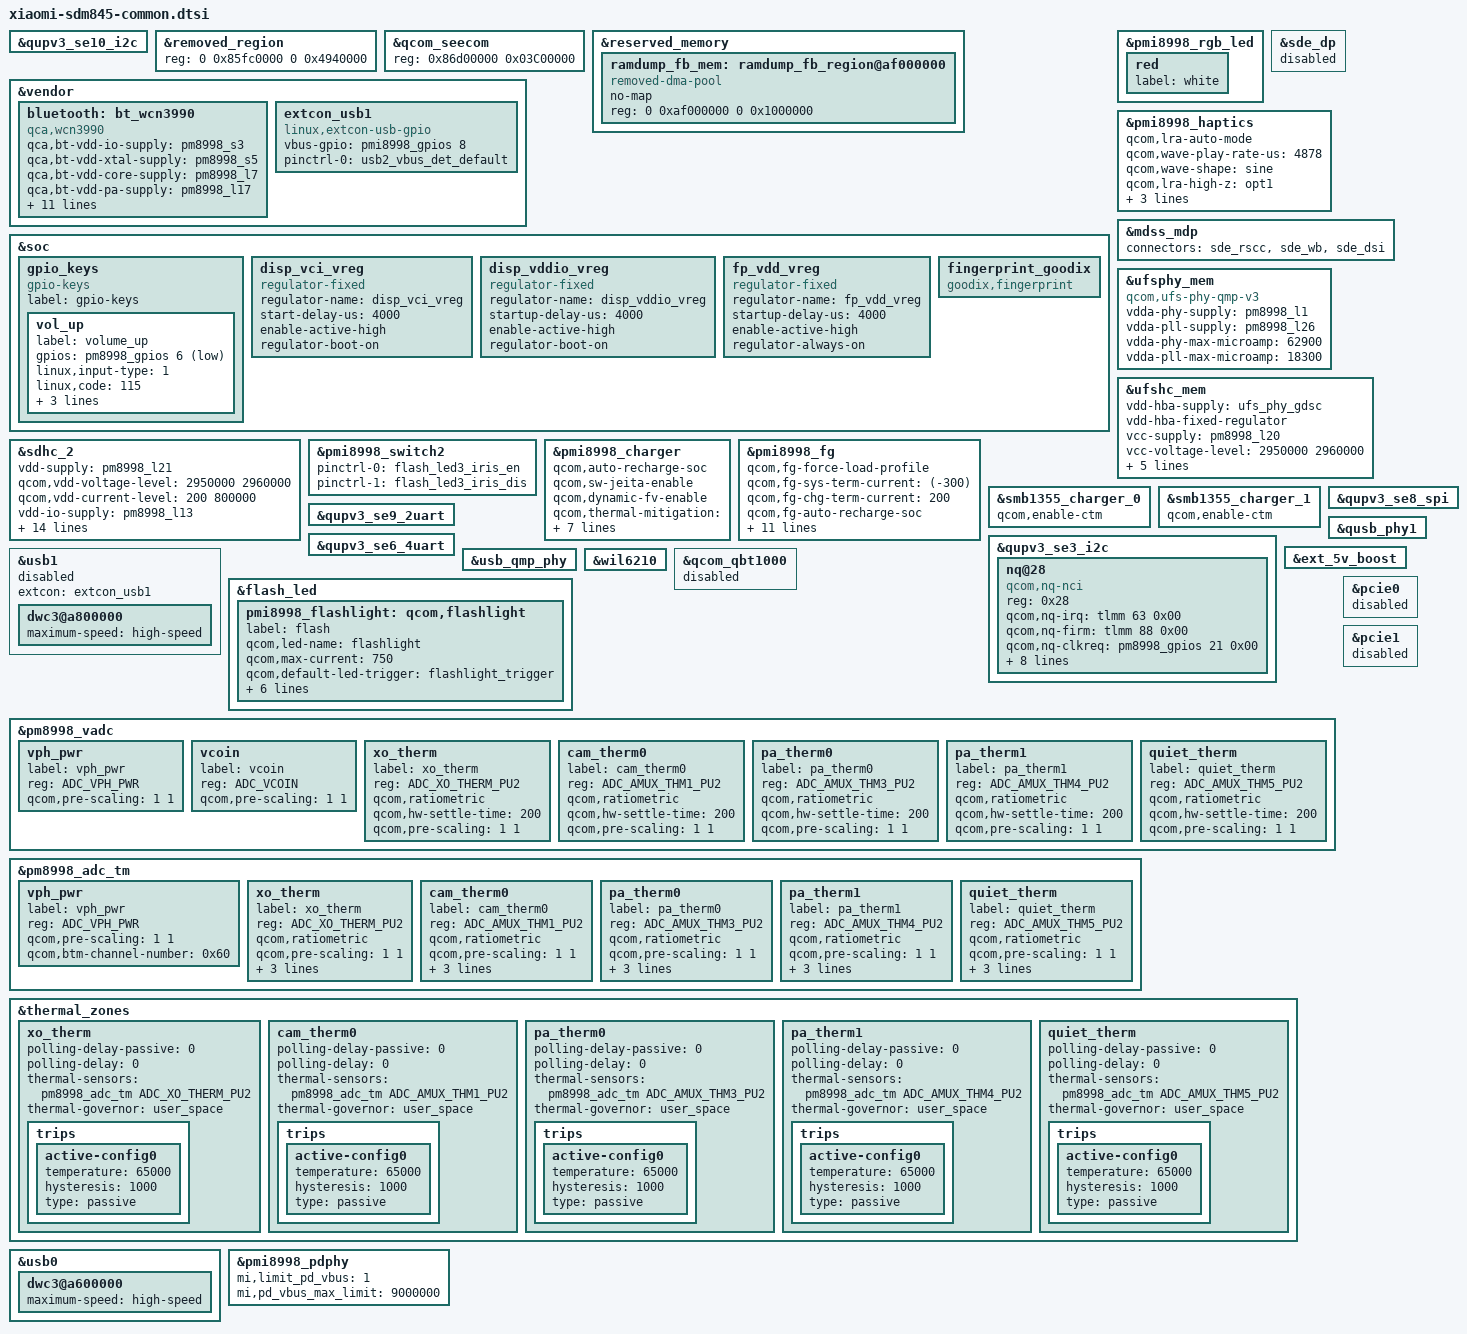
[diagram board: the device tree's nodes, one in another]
/* Copyright (c) 2017-2018, The Linux Foundation. All rights reserved.
 * Copyright (C) 2019 XiaoMi, Inc.
 *
 * This program is free software; you can redistribute it and/or modify
 * it under the terms of the GNU General Public License version 2 and
 * only version 2 as published by the Free Software Foundation.
 *
 * This program is distributed in the hope that it will be useful,
 * but WITHOUT ANY WARRANTY; without even the implied warranty of
 * MERCHANTABILITY or FITNESS FOR A PARTICULAR PURPOSE.  See the
 * GNU General Public License for more details.
 */

#include <dt-bindings/gpio/gpio.h>
#include "../sdm845-pmic-overlay.dtsi"
#include "../sdm845-pinctrl-overlay.dtsi"
#include "xiaomi-sde-display.dtsi"

&qupv3_se10_i2c {
#include "../../smb1355.dtsi"
};

&removed_region {
	reg = <0 0x85fc0000 0 0x4940000>;
};

&qcom_seecom {
	reg = <0x86d00000 0x03C00000>;
};

&reserved_memory {
		ramdump_fb_mem: ramdump_fb_region@af000000 {
			compatible = "removed-dma-pool";
			no-map;
			reg = <0 0xaf000000 0 0x1000000>;
		};
};

&vendor {
	bluetooth: bt_wcn3990 {
		compatible = "qca,wcn3990";
		qca,bt-vdd-io-supply = <&pm8998_s3>;
		qca,bt-vdd-xtal-supply = <&pm8998_s5>;
		qca,bt-vdd-core-supply = <&pm8998_l7>;
		qca,bt-vdd-pa-supply = <&pm8998_l17>;
		qca,bt-vdd-ldo-supply = <&pm8998_l25>;

		qca,bt-vdd-io-voltage-level = <1352000 1352000>;
		qca,bt-vdd-xtal-voltage-level = <2040000 2040000>;
		qca,bt-vdd-core-voltage-level = <1800000 1800000>;
		qca,bt-vdd-pa-voltage-level = <1304000 1304000>;
		qca,bt-vdd-ldo-voltage-level = <3312000 3312000>;

		qca,bt-vdd-io-current-level = <1>; /* LPM/PFM */
		qca,bt-vdd-xtal-current-level = <1>; /* LPM/PFM */
		qca,bt-vdd-core-current-level = <1>; /* LPM/PFM */
		qca,bt-vdd-pa-current-level = <1>; /* LPM/PFM */
		qca,bt-vdd-ldo-current-level = <1>; /* LPM/PFM */
	};
};

&soc {
	gpio_keys: gpio_keys {
		compatible = "gpio-keys";
		label = "gpio-keys";
		pinctrl-names = "default";
		vol_up {
			label = "volume_up";
			gpios = <&pm8998_gpios 6 GPIO_ACTIVE_LOW>;
			linux,input-type = <1>;
			linux,code = <115>;
			gpio-key,wakeup;
			debounce-interval = <15>;
			linux,can-disable;
		};
	};

	disp_vci_vreg: disp_vci_vreg {
		compatible = "regulator-fixed";
		regulator-name = "disp_vci_vreg";
		start-delay-us = <4000>;
		enable-active-high;
		regulator-boot-on;
	};

	disp_vddio_vreg: disp_vddio_vreg {
		compatible = "regulator-fixed";
		regulator-name = "disp_vddio_vreg";
		startup-delay-us = <4000>;
		enable-active-high;
		regulator-boot-on;
	 };

	fp_vdd_vreg: fp_vdd_vreg {
		compatible = "regulator-fixed";
		regulator-name = "fp_vdd_vreg";
		startup-delay-us = <4000>;
		enable-active-high;
		regulator-always-on;
	};

	fingerprint_goodix: fingerprint_goodix {
		compatible = "goodix,fingerprint";
		status = "ok";
	};
};

&pmi8998_rgb_led {
	red {
		label = "white";
	};
	/delete-node/ green;
	/delete-node/ blue;
};

&sde_dp {
	status = "disabled";
};

&pmi8998_haptics {
	qcom,lra-auto-mode;
	qcom,wave-play-rate-us = <4878>;
	qcom,wave-shape = "sine";
	qcom,lra-high-z = "opt1";
	qcom,lra-auto-res-mode = "qwd";
	qcom,lra-res-cal-period = <4>;
	qcom,effect-max = <3>;
	status = "okay";
};

&mdss_mdp {
	#cooling-cells = <2>;
	connectors = <&sde_rscc &sde_wb &sde_dsi>;
};

&ufsphy_mem {
	compatible = "qcom,ufs-phy-qmp-v3";
	vdda-phy-supply = <&pm8998_l1>; /* 0.88v */
	vdda-pll-supply = <&pm8998_l26>; /* 1.2v */
	vdda-phy-max-microamp = <62900>;
	vdda-pll-max-microamp = <18300>;
	status = "ok";
};

&ufshc_mem {
	vdd-hba-supply = <&ufs_phy_gdsc>;
	vdd-hba-fixed-regulator;
	vcc-supply = <&pm8998_l20>;
	vcc-voltage-level = <2950000 2960000>;
	vccq2-supply = <&pm8998_s4>;
	vcc-max-microamp = <600000>;
	vccq2-max-microamp = <600000>;

	qcom,vddp-ref-clk-supply = <&pm8998_l2>;
	qcom,vddp-ref-clk-max-microamp = <100>;

	status = "ok";
};

&sdhc_2 {
	vdd-supply = <&pm8998_l21>;
	qcom,vdd-voltage-level = <2950000 2960000>;
	qcom,vdd-current-level = <200 800000>;

	vdd-io-supply = <&pm8998_l13>;
	qcom,vdd-io-voltage-level = <1808000 2960000>;
	qcom,vdd-io-current-level = <200 22000>;

	pinctrl-names = "active", "sleep", "ds_400KHz",
			"ds_50MHz", "ds_100MHz", "ds_200MHz";
	pinctrl-0 = <&sdc2_clk_on  &sdc2_cmd_on &sdc2_data_on &storage_cd>;
	pinctrl-1 = <&sdc2_clk_off &sdc2_cmd_off &sdc2_data_off &storage_cd>;
	pinctrl-2 = <&sdc2_clk_ds_400KHz
			&sdc2_cmd_ds_400KHz &sdc2_data_ds_400KHz>;
	pinctrl-3 = <&sdc2_clk_ds_50MHz
			&sdc2_cmd_ds_50MHz &sdc2_data_ds_50MHz>;
	pinctrl-4 = <&sdc2_clk_ds_100MHz
			&sdc2_cmd_ds_100MHz &sdc2_data_ds_100MHz>;
	pinctrl-5 = <&sdc2_clk_ds_200MHz
			&sdc2_cmd_ds_200MHz &sdc2_data_ds_200MHz>;

	status = "ok";
};

&pmi8998_switch2 {
	pinctrl-names = "led_enable", "led_disable";
	pinctrl-0 = <&flash_led3_iris_en>;
	pinctrl-1 = <&flash_led3_iris_dis>;
};

&vendor{
	extcon_usb1: extcon_usb1 {
		compatible = "linux,extcon-usb-gpio";
		vbus-gpio = <&pmi8998_gpios 8 GPIO_ACTIVE_HIGH>;

		pinctrl-names = "default";
		pinctrl-0 = <&usb2_vbus_det_default>;
	};
};

&pmi8998_charger {
	qcom,auto-recharge-soc;
	qcom,sw-jeita-enable;
	qcom,dynamic-fv-enable;
	qcom,thermal-mitigation
				= <1800000 1600000 1400000 1200000 1000000 1000000 1000000>;
	qcom,thermal-mitigation-dcp
				= <1800000 1800000 1800000 1800000 1800000 1800000 1800000
				   1800000 1800000 1800000 1800000 1800000 1600000 1400000
				   1200000 1000000>;
	qcom,thermal-mitigation-qc2
				= <1625000 1625000 1625000 1625000 1625000 1525000 1425000
				   1325000 1225000 1125000 10255000 925000 825000 725000
				   625000 525000>;
	qcom,thermal-mitigation-pd-base
				= <3000000 2800000 2600000 2400000 2200000 2000000 1800000
				   1600000 1600000 1400000 1200000 1100000 1000000 900000
				   752500 525000>;
};

&pmi8998_fg {
	qcom,fg-force-load-profile;
	qcom,fg-sys-term-current = <(-300)>;
	qcom,fg-chg-term-current = <200>;
	qcom,fg-auto-recharge-soc;
	qcom,fg-recharge-soc-thr = <99>;
	qcom,fg-cutoff-voltage = <3400>;
	qcom,fg-cutoff-current = <200>;
	qcom,fg-empty-voltage = <3100>;
	qcom,fg-jeita-hyst-temp = <2>;
	qcom,fg-jeita-thresholds = <0 15 45 60>;
	qcom,fg-esr-clamp-mohms = <60>;
	qcom,fg-batt-temp-delta = <6>;
	qcom,battery-data = <&mtp_batterydata>;
	qcom,slope-limit-temp-threshold = <100>;
	qcom,slope-limit-coeffs = <10 11 12 13>;
};

&smb1355_charger_0 {
	status = "ok";
	qcom,enable-ctm;
};

&smb1355_charger_1 {
	status = "ok";
	qcom,enable-ctm;
};

&qupv3_se9_2uart {
	status = "ok";
};

&qupv3_se8_spi {
	status = "ok";
};

&qupv3_se3_i2c {
	nq@28 {
		compatible = "qcom,nq-nci";
		reg = <0x28>;
		qcom,nq-irq = <&tlmm 63 0x00>;
		qcom,nq-firm = <&tlmm 88 0x00>;
		qcom,nq-clkreq = <&pm8998_gpios 21 0x00>;
		qcom,nq-esepwr = <&tlmm 116 0x00>;
		interrupt-parent = <&tlmm>;
		qcom,clk-src = "BBCLK3";
		interrupts = <63 0>;
		interrupt-names = "nfc_irq";
		pinctrl-names = "nfc_active", "nfc_suspend";
		pinctrl-0 = <&nfc_int_active
			 &nfc_enable_active
			 &nfc_clk_default>;
		pinctrl-1 = <&nfc_int_suspend &nfc_enable_suspend>;
		clocks = <&clock_rpmh RPMH_LN_BB_CLK3>;
		clock-names = "ref_clk";
	};
};

&qupv3_se6_4uart {
	status = "ok";
};

&usb1 {
	status = "disabled";
	extcon = <&extcon_usb1>;
};

&qusb_phy1 {
	status = "okay";
};

&ext_5v_boost {
	status = "ok";
};

&usb_qmp_phy {
	status = "okay";
};

&wil6210 {
	status = "ok";
};

&flash_led {
	pmi8998_flashlight: qcom,flashlight {
		label = "flash";
		qcom,led-name = "flashlight";
		qcom,max-current = <750>;
		qcom,default-led-trigger = "flashlight_trigger";
		qcom,id = <3>;
		qcom,current-ma = <500>;
		qcom,duration-ms = <1280>;
		qcom,ires-ua = <12500>;
		qcom,hdrm-voltage-mv = <325>;
		qcom,hdrm-vol-hi-lo-win-mv = <100>;
	};
};

&qcom_qbt1000 {
	status = "disabled";
};

&pm8998_vadc {
	vph_pwr {
		label = "vph_pwr";
		reg = <ADC_VPH_PWR>;
		qcom,pre-scaling = <1 1>;
	};

	vcoin {
		label = "vcoin";
		reg = <ADC_VCOIN>;
		qcom,pre-scaling = <1 1>;
	};

	xo_therm {
		label = "xo_therm";
		reg = <ADC_XO_THERM_PU2>;
		qcom,ratiometric;
		qcom,hw-settle-time = <200>;
		qcom,pre-scaling = <1 1>;
	};

	cam_therm0 {
		label = "cam_therm0";
		reg = <ADC_AMUX_THM1_PU2>;
		qcom,ratiometric;
		qcom,hw-settle-time = <200>;
		qcom,pre-scaling = <1 1>;
	};

	pa_therm0 {
		label = "pa_therm0";
		reg = <ADC_AMUX_THM3_PU2>;
		qcom,ratiometric;
		qcom,hw-settle-time = <200>;
		qcom,pre-scaling = <1 1>;
	};

	pa_therm1 {
		label = "pa_therm1";
		reg = <ADC_AMUX_THM4_PU2>;
		qcom,ratiometric;
		qcom,hw-settle-time = <200>;
		qcom,pre-scaling = <1 1>;
	};

	quiet_therm {
		label = "quiet_therm";
		reg = <ADC_AMUX_THM5_PU2>;
		qcom,ratiometric;
		qcom,hw-settle-time = <200>;
		qcom,pre-scaling = <1 1>;
	};
};

&pm8998_adc_tm {
	vph_pwr {
		label = "vph_pwr";
		reg = <ADC_VPH_PWR>;
		qcom,pre-scaling = <1 1>;
		qcom,btm-channel-number = <0x60>;
	};

	xo_therm {
		label = "xo_therm";
		reg = <ADC_XO_THERM_PU2>;
		qcom,ratiometric;
		qcom,pre-scaling = <1 1>;
		qcom,hw-settle-time = <200>;
		qcom,btm-channel-number = <0x68>;
		qcom,thermal-node;
	};

	cam_therm0 {
		label = "cam_therm0";
		reg = <ADC_AMUX_THM1_PU2>;
		qcom,ratiometric;
		qcom,pre-scaling = <1 1>;
		qcom,hw-settle-time = <200>;
		qcom,btm-channel-number = <0x88>;
		qcom,thermal-node;
	};

	pa_therm0 {
		label = "pa_therm0";
		reg = <ADC_AMUX_THM3_PU2>;
		qcom,ratiometric;
		qcom,pre-scaling = <1 1>;
		qcom,hw-settle-time = <200>;
		qcom,btm-channel-number = <0x78>;
		qcom,thermal-node;
	};

	pa_therm1 {
		label = "pa_therm1";
		reg = <ADC_AMUX_THM4_PU2>;
		qcom,ratiometric;
		qcom,pre-scaling = <1 1>;
		qcom,hw-settle-time = <200>;
		qcom,btm-channel-number = <0x90>;
		qcom,thermal-node;
	};

	quiet_therm {
		label = "quiet_therm";
		reg = <ADC_AMUX_THM5_PU2>;
		qcom,ratiometric;
		qcom,pre-scaling = <1 1>;
		qcom,hw-settle-time = <200>;
		qcom,btm-channel-number = <0x80>;
		qcom,thermal-node;
	};
};

&thermal_zones {
	xo_therm {
		polling-delay-passive = <0>;
		polling-delay = <0>;
		thermal-sensors = <&pm8998_adc_tm ADC_XO_THERM_PU2>;
		thermal-governor = "user_space";

		trips {
			active-config0 {
				temperature = <65000>;
				hysteresis = <1000>;
				type = "passive";
			};
		};
	};

	cam_therm0 {
		polling-delay-passive = <0>;
		polling-delay = <0>;
		thermal-sensors = <&pm8998_adc_tm ADC_AMUX_THM1_PU2>;
		thermal-governor = "user_space";

		trips {
			active-config0 {
					temperature = <65000>;
					hysteresis = <1000>;
					type = "passive";
			};
		};
	};

	pa_therm0 {
		polling-delay-passive = <0>;
		polling-delay = <0>;
		thermal-sensors = <&pm8998_adc_tm ADC_AMUX_THM3_PU2>;
		thermal-governor = "user_space";

		trips {
			active-config0 {
					temperature = <65000>;
					hysteresis = <1000>;
					type = "passive";
			};
		};
	};

	pa_therm1 {
		polling-delay-passive = <0>;
		polling-delay = <0>;
		thermal-sensors = <&pm8998_adc_tm ADC_AMUX_THM4_PU2>;
		thermal-governor = "user_space";

		trips {
			active-config0 {
					temperature = <65000>;
					hysteresis = <1000>;
					type = "passive";
			};
		};
	};

	quiet_therm {
		polling-delay-passive = <0>;
		polling-delay = <0>;
		thermal-sensors = <&pm8998_adc_tm ADC_AMUX_THM5_PU2>;
		thermal-governor = "user_space";

		trips {
			active-config0 {
				temperature = <65000>;
				hysteresis = <1000>;
				type = "passive";
			};
		};
	};
};

&usb0 {
	dwc3@a600000 {
		maximum-speed = "high-speed";
	};
};

&usb1 {
	dwc3@a800000 {
		maximum-speed = "high-speed";
	};
};

&pcie0 {
	status = "disabled";
};

&pcie1 {
	status = "disabled";
};

&pmi8998_pdphy {
	/*mi,limit_pd_vbus 1:enable 0:disable*/
	mi,limit_pd_vbus = <1>;
	mi,pd_vbus_max_limit = <9000000>;
};
